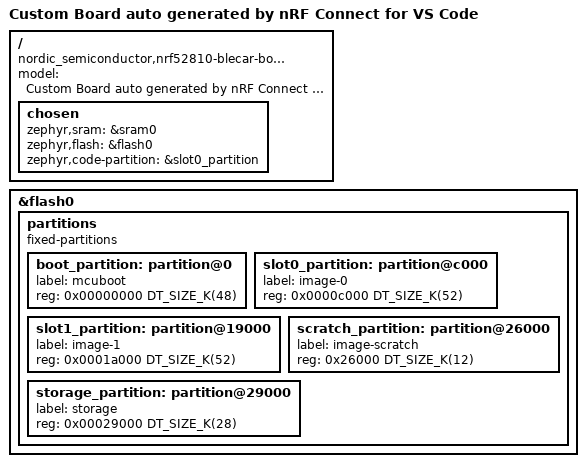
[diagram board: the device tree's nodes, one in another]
/dts-v1/;
#include <nordic/nrf52810_qfaa.dtsi>
#include "nrf52810_blecar_board-pinctrl.dtsi"

/ {
	model = "Custom Board auto generated by nRF Connect for VS Code";
	compatible = "nordic_semiconductor,nrf52810-blecar-board";

	chosen {
		zephyr,sram = &sram0;
		zephyr,flash = &flash0;
		zephyr,code-partition = &slot0_partition;
	};
};

&flash0 {
	partitions {
		compatible = "fixed-partitions";
		#address-cells = <1>;
		#size-cells = <1>;

		boot_partition: partition@0 {
			label = "mcuboot";
			reg = <0x00000000 DT_SIZE_K(48)>;
		};

		slot0_partition: partition@c000 {
			label = "image-0";
			reg = <0x0000c000 DT_SIZE_K(52)>;
		};

		slot1_partition: partition@19000 {
			label = "image-1";
			reg = <0x0001a000 DT_SIZE_K(52)>;
		};

		scratch_partition: partition@26000 {
			label = "image-scratch";
			reg = <0x26000 DT_SIZE_K(12)>;
		};

		storage_partition: partition@29000 {
			label = "storage";
			reg = <0x00029000 DT_SIZE_K(28)>;
		};

	};
};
